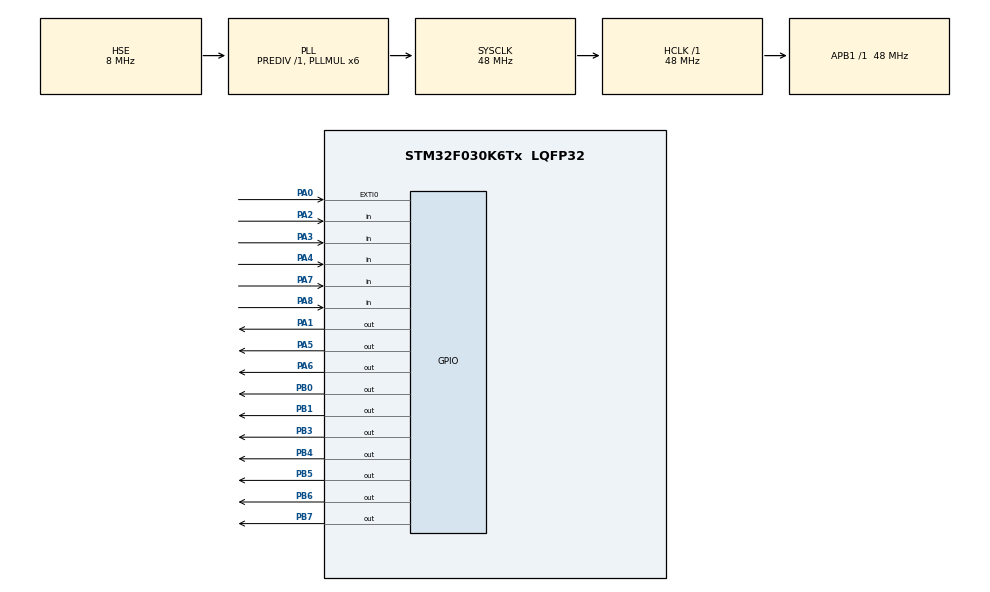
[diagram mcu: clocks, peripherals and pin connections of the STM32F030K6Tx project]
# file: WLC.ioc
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IWDG.Prescaler=IWDG_PRESCALER_128
IWDG.Reload=1000-1
IWDG.Window=1000-1
Mcu.Family=STM32F0
Mcu.Name=STM32F030K6Tx
Mcu.Package=LQFP32
NVIC.EXTI0_1_IRQn=true\:0\:0\:false\:false\:true\:true\:true
NVIC.TIM14_IRQn=true\:0\:0\:false\:false\:true\:true\:true
PA0.GPIO_ModeDefaultEXTI=GPIO_MODE_IT_RISING_FALLING
PA0.Signal=GPXTI0
PA1.GPIO_PuPd=GPIO_PULLDOWN
PA1.GPIO_Speed=GPIO_SPEED_FREQ_HIGH
PA1.Signal=GPIO_Output
PA2.GPIO_PuPd=GPIO_PULLUP
PA2.Signal=GPIO_Input
PA3.GPIO_PuPd=GPIO_PULLUP
PA3.Signal=GPIO_Input
PA4.GPIO_PuPd=GPIO_PULLUP
PA4.Signal=GPIO_Input
PA5.GPIO_PuPd=GPIO_PULLDOWN
PA5.Signal=GPIO_Output
PA6.GPIO_PuPd=GPIO_PULLDOWN
PA6.Signal=GPIO_Output
PA7.GPIO_PuPd=GPIO_PULLUP
PA7.Signal=GPIO_Input
PA8.GPIO_PuPd=GPIO_PULLUP
PA8.Signal=GPIO_Input
PB0.GPIO_Speed=GPIO_SPEED_FREQ_HIGH
PB0.Signal=GPIO_Output
PB1.GPIO_Speed=GPIO_SPEED_FREQ_HIGH
PB1.Signal=GPIO_Output
PB3.GPIO_Speed=GPIO_SPEED_FREQ_HIGH
PB3.Signal=GPIO_Output
PB4.GPIO_Speed=GPIO_SPEED_FREQ_HIGH
PB4.Signal=GPIO_Output
PB5.GPIO_Speed=GPIO_SPEED_FREQ_HIGH
PB5.Signal=GPIO_Output
PB6.GPIO_Speed=GPIO_SPEED_FREQ_HIGH
PB6.Signal=GPIO_Output
PB7.GPIO_Speed=GPIO_SPEED_FREQ_HIGH
PB7.Signal=GPIO_Output
PF0-OSC_IN.Mode=HSE-External-Oscillator
PF0-OSC_IN.Signal=RCC_OSC_IN
PF1-OSC_OUT.Mode=HSE-External-Oscillator
PF1-OSC_OUT.Signal=RCC_OSC_OUT
ProjectManager.HeapSize=0x200
ProjectManager.StackSize=0x400
ProjectManager.TargetToolchain=STM32CubeIDE
RCC.AHBFreq_Value=48000000
RCC.APB1Freq_Value=48000000
RCC.APB1TimFreq_Value=48000000
RCC.HCLKFreq_Value=48000000
RCC.PLLMUL=RCC_PLL_MUL6
RCC.PLLSourceVirtual=RCC_PLLSOURCE_HSE
RCC.SYSCLKFreq_VALUE=48000000
RCC.SYSCLKSource=RCC_SYSCLKSOURCE_PLLCLK
TIM14.Prescaler=48-1
VP_IWDG_VS_IWDG.Mode=IWDG_Activate
VP_TIM14_VS_ClockSourceINT.Mode=Enable_Timer
board=custom

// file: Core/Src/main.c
/* USER CODE BEGIN Header */
/**
  ******************************************************************************
  * @file           : main.c
  * @brief          : Main program body
  ******************************************************************************
  * @attention
  *
  * <h2><center>&copy; Copyright (c) 2020 STMicroelectronics.
  * All rights reserved.</center></h2>
  *
  * This software component is licensed by ST under BSD 3-Clause license,
  * the "License"; You may not use this file except in compliance with the
  * License. You may obtain a copy of the License at:
  *                        opensource.org/licenses/BSD-3-Clause
  *
  ******************************************************************************
  */
/* USER CODE END Header */
#include "main.h"

/* USER CODE BEGIN Includes */
#include "lcd.h"
#include "range.h"
#include "stdio.h"
#include "gui.h"
#include "eeprom.h"
/* USER CODE END Includes */

IWDG_HandleTypeDef hiwdg;

TIM_HandleTypeDef htim14;

void SystemClock_Config(void);
static void MX_GPIO_Init(void);
static void MX_TIM14_Init(void);
static void MX_IWDG_Init(void);

int main(void)
{

  /* MCU Configuration--------------------------------------------------------*/

  /* Reset of all peripherals, Initializes the Flash interface and the Systick. */
  HAL_Init();

  /* Configure the system clock */
  SystemClock_Config();

  /* USER CODE BEGIN SysInit */

  // Unlocks the Flash Program Erase controller and Configures Flash -> EEPROM

  /* USER CODE END SysInit */

  /* Initialize all configured peripherals */
  MX_GPIO_Init();
  MX_TIM14_Init();
  MX_IWDG_Init();
  /* USER CODE BEGIN 2 */
  HAL_IWDG_Refresh(&hiwdg);

  HAL_FLASH_Unlock();
  EE_Init();
  gui();

  /* USER CODE END 2 */

  /* Infinite loop */
  while (1)
  {

  }
}

void SystemClock_Config(void)
{
  RCC_OscInitTypeDef RCC_OscInitStruct = {0};
  RCC_ClkInitTypeDef RCC_ClkInitStruct = {0};

  /** Initializes the RCC Oscillators according to the specified parameters
  * in the RCC_OscInitTypeDef structure.
  */
  RCC_OscInitStruct.OscillatorType = RCC_OSCILLATORTYPE_LSI|RCC_OSCILLATORTYPE_HSE;
  RCC_OscInitStruct.HSEState = RCC_HSE_ON;
  RCC_OscInitStruct.LSIState = RCC_LSI_ON;
  RCC_OscInitStruct.PLL.PLLState = RCC_PLL_ON;
  RCC_OscInitStruct.PLL.PLLSource = RCC_PLLSOURCE_HSE;
  RCC_OscInitStruct.PLL.PLLMUL = RCC_PLL_MUL6;
  RCC_OscInitStruct.PLL.PREDIV = RCC_PREDIV_DIV1;
  if (HAL_RCC_OscConfig(&RCC_OscInitStruct) != HAL_OK)
  {
    Error_Handler();
  }
  /** Initializes the CPU, AHB and APB buses clocks
  */
  RCC_ClkInitStruct.ClockType = RCC_CLOCKTYPE_HCLK|RCC_CLOCKTYPE_SYSCLK
                              |RCC_CLOCKTYPE_PCLK1;
  RCC_ClkInitStruct.SYSCLKSource = RCC_SYSCLKSOURCE_PLLCLK;
  RCC_ClkInitStruct.AHBCLKDivider = RCC_SYSCLK_DIV1;
  RCC_ClkInitStruct.APB1CLKDivider = RCC_HCLK_DIV1;

  if (HAL_RCC_ClockConfig(&RCC_ClkInitStruct, FLASH_LATENCY_1) != HAL_OK)
  {
    Error_Handler();
  }
}

static void MX_IWDG_Init(void)
{

  hiwdg.Instance = IWDG;
  hiwdg.Init.Prescaler = IWDG_PRESCALER_128;
  hiwdg.Init.Window = 1000-1;
  hiwdg.Init.Reload = 1000-1;
  if (HAL_IWDG_Init(&hiwdg) != HAL_OK)
  {
    Error_Handler();
  }

}

static void MX_TIM14_Init(void)
{

  htim14.Instance = TIM14;
  htim14.Init.Prescaler = 48-1;
  htim14.Init.CounterMode = TIM_COUNTERMODE_UP;
  htim14.Init.Period = 65535;
  htim14.Init.ClockDivision = TIM_CLOCKDIVISION_DIV1;
  htim14.Init.AutoReloadPreload = TIM_AUTORELOAD_PRELOAD_DISABLE;
  if (HAL_TIM_Base_Init(&htim14) != HAL_OK)
  {
    Error_Handler();
  }

}

static void MX_GPIO_Init(void)
{
  GPIO_InitTypeDef GPIO_InitStruct = {0};

  /* GPIO Ports Clock Enable */
  __HAL_RCC_GPIOF_CLK_ENABLE();
  __HAL_RCC_GPIOA_CLK_ENABLE();
  __HAL_RCC_GPIOB_CLK_ENABLE();

  /*Configure GPIO pin Output Level */
  HAL_GPIO_WritePin(GPIOA, GPIO_PIN_1|GPIO_PIN_5|GPIO_PIN_6, GPIO_PIN_RESET);

  /*Configure GPIO pin Output Level */
  HAL_GPIO_WritePin(GPIOB, GPIO_PIN_0|GPIO_PIN_1|GPIO_PIN_3|GPIO_PIN_4
                          |GPIO_PIN_5|GPIO_PIN_6|GPIO_PIN_7, GPIO_PIN_RESET);

  /*Configure GPIO pin : PA0 */
  GPIO_InitStruct.Pin = GPIO_PIN_0;
  GPIO_InitStruct.Mode = GPIO_MODE_IT_RISING_FALLING;
  GPIO_InitStruct.Pull = GPIO_NOPULL;
  HAL_GPIO_Init(GPIOA, &GPIO_InitStruct);

  /*Configure GPIO pin : PA1 */
  GPIO_InitStruct.Pin = GPIO_PIN_1;
  GPIO_InitStruct.Mode = GPIO_MODE_OUTPUT_PP;
  GPIO_InitStruct.Pull = GPIO_PULLDOWN;
  GPIO_InitStruct.Speed = GPIO_SPEED_FREQ_HIGH;
  HAL_GPIO_Init(GPIOA, &GPIO_InitStruct);

  /*Configure GPIO pins : PA2 PA3 PA4 PA7
                           PA8 */
  GPIO_InitStruct.Pin = GPIO_PIN_2|GPIO_PIN_3|GPIO_PIN_4|GPIO_PIN_7
                          |GPIO_PIN_8;
  GPIO_InitStruct.Mode = GPIO_MODE_INPUT;
  GPIO_InitStruct.Pull = GPIO_PULLUP;
  HAL_GPIO_Init(GPIOA, &GPIO_InitStruct);

  /*Configure GPIO pins : PA5 PA6 */
  GPIO_InitStruct.Pin = GPIO_PIN_5|GPIO_PIN_6;
  GPIO_InitStruct.Mode = GPIO_MODE_OUTPUT_PP;
  GPIO_InitStruct.Pull = GPIO_PULLDOWN;
  GPIO_InitStruct.Speed = GPIO_SPEED_FREQ_LOW;
  HAL_GPIO_Init(GPIOA, &GPIO_InitStruct);

  /*Configure GPIO pins : PB0 PB1 PB3 PB4
                           PB5 PB6 PB7 */
  GPIO_InitStruct.Pin = GPIO_PIN_0|GPIO_PIN_1|GPIO_PIN_3|GPIO_PIN_4
                          |GPIO_PIN_5|GPIO_PIN_6|GPIO_PIN_7;
  GPIO_InitStruct.Mode = GPIO_MODE_OUTPUT_PP;
  GPIO_InitStruct.Pull = GPIO_NOPULL;
  GPIO_InitStruct.Speed = GPIO_SPEED_FREQ_HIGH;
  HAL_GPIO_Init(GPIOB, &GPIO_InitStruct);

  /* EXTI interrupt init*/
  HAL_NVIC_SetPriority(EXTI0_1_IRQn, 0, 0);
  HAL_NVIC_EnableIRQ(EXTI0_1_IRQn);

}

void Error_Handler(void)
{
}

/************************ (C) COPYRIGHT STMicroelectronics *****END OF FILE****/
